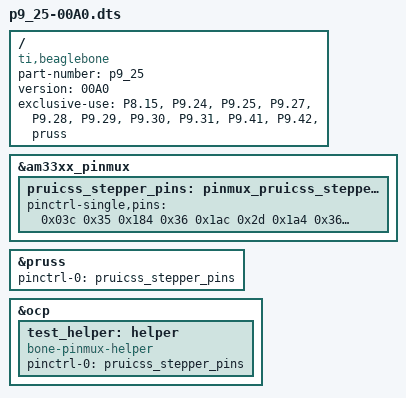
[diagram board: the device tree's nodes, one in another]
/dts-v1/;
/plugin/;

/ {
    compatible = "ti,beaglebone", "ti,beaglebone-black";

    /* identification */
    part-number = "p9_25";

    /* version */
    version = "00A0";

    /* state the resources this cape uses or prepare to get winged! */
    exclusive-use =
        /* the pin header P9 uses */
        "P8.15",
        "P9.24",
        "P9.25",
        "P9.27",
        "P9.28",
        "P9.29",
        "P9.30",
        "P9.31",
        "P9.41",
        "P9.42",
        /* Hardware IP cores in use */
        "pruss"; 

    fragment@0 {
        target = <&am33xx_pinmux>;
        __overlay__ {
            pruicss_stepper_pins: pinmux_pruicss_stepper_pins{
                pinctrl-single,pins = <
                     // All inputs pullup
                     // All outputs fast pullup disabled
                     // These go to PRU0
                    0x03c 0x35 // IN  P8_15 = pr1_ecap0
                    0x184 0x36 // IN  P9_24 = pr1_pru0_pru_31_16
                    0x1ac 0x2d // OUT P9_25 = pr1_pru0_pru_30_7
                    0x1a4 0x36 // IN  P9_27 = pr1_pru0_pru_31_5
                    0x19c 0x36 // IN  P9_28 = pr1_pru0_pru_31_3
                    0x194 0x36 // IN  P9_29 = pr1_pru0_pru_31_1
                    0x198 0x36 // IN  P9_30 = pr1_pru0_pru_31_2
                    0x190 0x2d // OUT P9_31 = pr1_pru0_pru_30_0
                    0x1a8 0x2d // OUT P9_41 = pr1_pru0_pru_30_6
                    0x1a0 0x36 // IN  P9_42 = pr1_pru0_pru_31_4

                     // These are GPIO
                    0x15C 0x2f // OUT  P9_17 = gpio0_5
                    0x158 0x2f // OUT  P9_18 = gpio0_4
                    0x150 0x2f // OUT  P9_22 = gpio0_2
                    0x154 0x2f // OUT  P9_21 = gpio0_3
                    0x020 0x2f // OUT  P8_19 = gpio0_22
                    0x024 0x2f // OUT  P8_13 = gpio0_23
                    0x028 0x2f // OUT  P8_14 = gpio0_26
                    0x02c 0x2f // OUT  P8_17 = gpio0_27
                >;
            };        

        };
    };

    fragment@1{
        target = <&pruss>;
        __overlay__{
            status = "okay";
            pinctrl-names = "default";
            pinctrl-0       = <&pruicss_stepper_pins>;

        };
    };
    fragment@2 {
        target = <&ocp>;
        __overlay__ {
            test_helper: helper {
                compatible = "bone-pinmux-helper";
                pinctrl-names = "default";
                pinctrl-0 = <&pruicss_stepper_pins>;
                status = "okay";
            };
        };
   };
};
